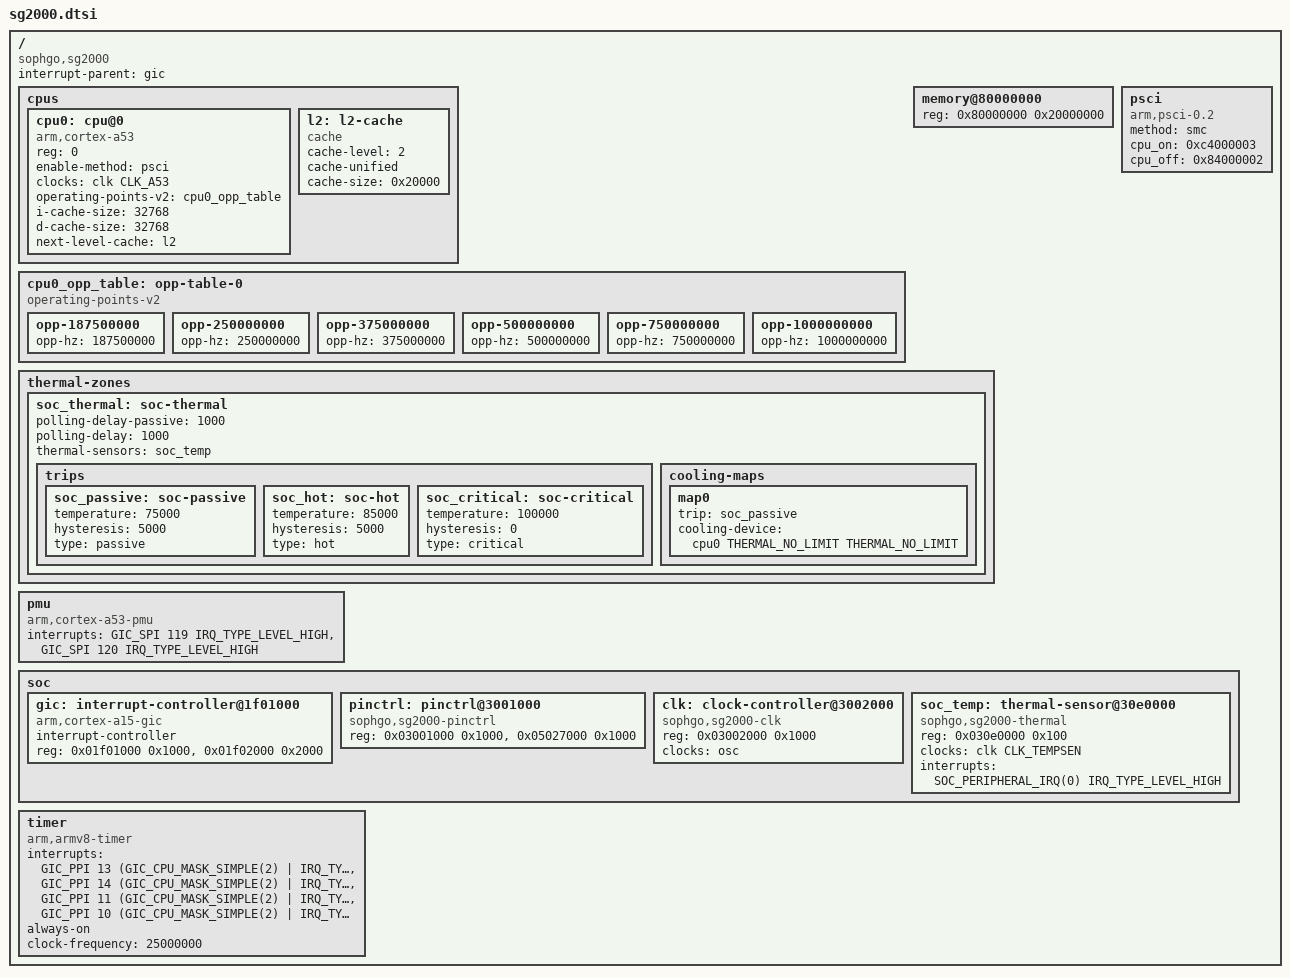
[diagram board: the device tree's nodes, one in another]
// SPDX-License-Identifier: (GPL-2.0 OR MIT)

#define SOC_PERIPHERAL_IRQ(nr)		GIC_SPI (nr)

#include <dt-bindings/interrupt-controller/arm-gic.h>
#include <dt-bindings/thermal/thermal.h>
#include <riscv/sophgo/cv180x.dtsi>
#include <riscv/sophgo/cv181x.dtsi>

/ {
	compatible = "sophgo,sg2000";
	interrupt-parent = <&gic>;

	cpus {
		#address-cells = <1>;
		#size-cells = <0>;

		cpu0: cpu@0 {
			compatible = "arm,cortex-a53";
			device_type = "cpu";
			reg = <0>;
			enable-method = "psci";
			clocks = <&clk CLK_A53>;
			operating-points-v2 = <&cpu0_opp_table>;
			#cooling-cells = <2>;
			i-cache-size = <32768>;
			d-cache-size = <32768>;
			next-level-cache = <&l2>;
		};

		l2: l2-cache {
			compatible = "cache";
			cache-level = <2>;
			cache-unified;
			cache-size = <0x20000>;
		};
	};

	/*
	 * A53 operating points.  Only exact integer divisions of the two CPU
	 * clock sources are listed: MPLL (1 GHz) and FPLL (1.5 GHz).  Their
	 * rates are fixed by the SoC; the clock driver performs the glitch-free
	 * source/divider switch.  There is no CPU voltage scaling on SG2000.
	 */
	cpu0_opp_table: opp-table-0 {
		compatible = "operating-points-v2";

		opp-187500000 {
			opp-hz = /bits/ 64 <187500000>;
		};

		opp-250000000 {
			opp-hz = /bits/ 64 <250000000>;
		};

		opp-375000000 {
			opp-hz = /bits/ 64 <375000000>;
		};

		opp-500000000 {
			opp-hz = /bits/ 64 <500000000>;
		};

		opp-750000000 {
			opp-hz = /bits/ 64 <750000000>;
		};

		opp-1000000000 {
			opp-hz = /bits/ 64 <1000000000>;
		};
	};

	memory@80000000 {
		device_type = "memory";
		reg = <0x80000000 0x20000000>;	/* 512MiB */
	};

	/*
	 * The zone is SoC-wide.  The passive trip is bound to the A53 cpufreq
	 * cooling device (cpufreq-dt), the hot trip notifies userspace, and the
	 * critical trip is the kernel thermal core's last-resort orderly
	 * shutdown.  The hardware thermal-shutdown path is off by default and
	 * is not enabled here.
	 */
	thermal-zones {
		soc_thermal: soc-thermal {
			polling-delay-passive = <1000>;
			polling-delay = <1000>;
			thermal-sensors = <&soc_temp>;

			trips {
				soc_passive: soc-passive {
					temperature = <75000>;
					hysteresis = <5000>;
					type = "passive";
				};

				soc_hot: soc-hot {
					temperature = <85000>;
					hysteresis = <5000>;
					type = "hot";
				};

				soc_critical: soc-critical {
					temperature = <100000>;
					hysteresis = <0>;
					type = "critical";
				};
			};

			cooling-maps {
				map0 {
					trip = <&soc_passive>;
					cooling-device = <&cpu0 THERMAL_NO_LIMIT THERMAL_NO_LIMIT>;
				};
			};
		};
	};

	pmu {
		compatible = "arm,cortex-a53-pmu";
		interrupts = <GIC_SPI 119 IRQ_TYPE_LEVEL_HIGH>,
			     <GIC_SPI 120 IRQ_TYPE_LEVEL_HIGH>;
	};

	psci {
		compatible = "arm,psci-0.2";
		method = "smc";
		cpu_on = <0xc4000003>;
		cpu_off = <0x84000002>;
	};

	soc {
		gic: interrupt-controller@1f01000 {
			compatible = "arm,cortex-a15-gic";
			interrupt-controller;
			#interrupt-cells = <3>;
			reg = <0x01f01000 0x1000>,
			      <0x01f02000 0x2000>;
		};

		pinctrl: pinctrl@3001000 {
			compatible = "sophgo,sg2000-pinctrl";
			reg = <0x03001000 0x1000>,
			      <0x05027000 0x1000>;
			reg-names = "sys", "rtc";
		};

		clk: clock-controller@3002000 {
			compatible = "sophgo,sg2000-clk";
			reg = <0x03002000 0x1000>;
			clocks = <&osc>;
			#clock-cells = <1>;
		};

		soc_temp: thermal-sensor@30e0000 {
			compatible = "sophgo,sg2000-thermal", "sophgo,cv1800b-thermal";
			reg = <0x030e0000 0x100>;
			clocks = <&clk CLK_TEMPSEN>;
			interrupts = <SOC_PERIPHERAL_IRQ(0) IRQ_TYPE_LEVEL_HIGH>;
			#thermal-sensor-cells = <0>;
		};
	};

	timer {
		compatible = "arm,armv8-timer";
		interrupts = <GIC_PPI 13 (GIC_CPU_MASK_SIMPLE(2) | IRQ_TYPE_LEVEL_LOW)>,
			     <GIC_PPI 14 (GIC_CPU_MASK_SIMPLE(2) | IRQ_TYPE_LEVEL_LOW)>,
			     <GIC_PPI 11 (GIC_CPU_MASK_SIMPLE(2) | IRQ_TYPE_LEVEL_LOW)>,
			     <GIC_PPI 10 (GIC_CPU_MASK_SIMPLE(2) | IRQ_TYPE_LEVEL_LOW)>;
		always-on;
		clock-frequency = <25000000>;
	};
};
